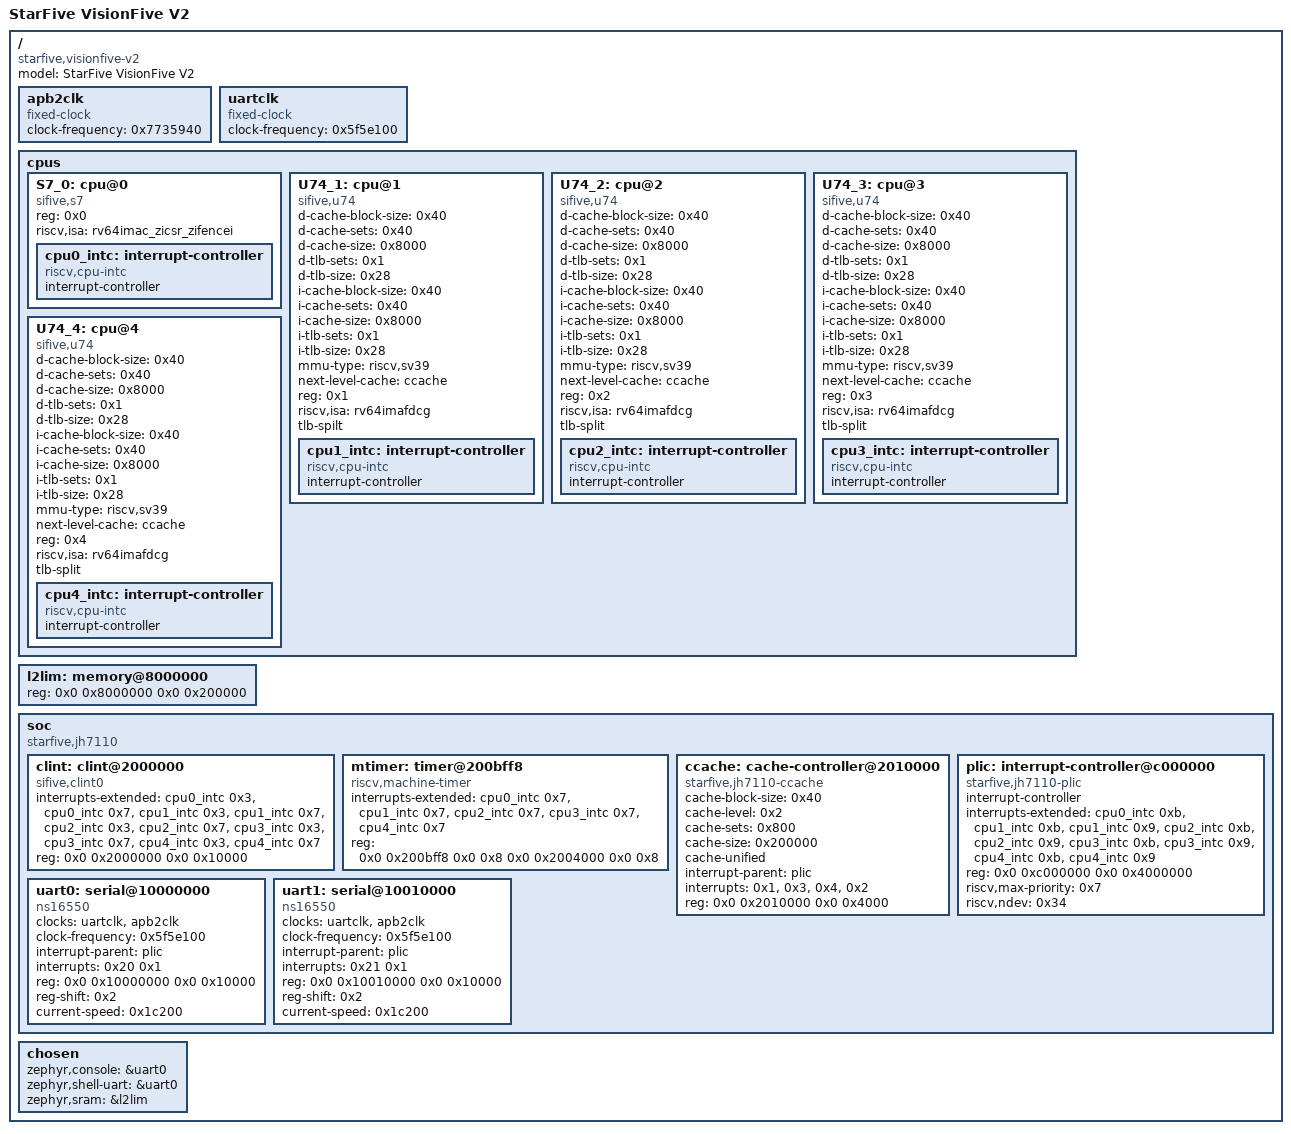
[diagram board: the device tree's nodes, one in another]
/dts-v1/;

/* node '/' defined in zephyr/dts/riscv/starfive/jh7110-clk.dtsi:8 */
/ {
	#address-cells = < 0x2 >;              /* in zephyr/dts/riscv/starfive/jh7110-visionfive-v2.dtsi:13 */
	#size-cells = < 0x2 >;                 /* in zephyr/dts/riscv/starfive/jh7110-visionfive-v2.dtsi:14 */
	model = "StarFive VisionFive V2";      /* in zephyr/boards/starfive/visionfive2/visionfive2.dts:12 */
	compatible = "starfive,visionfive-v2"; /* in zephyr/boards/starfive/visionfive2/visionfive2.dts:13 */

	/* node '/apb2clk' defined in zephyr/dts/riscv/starfive/jh7110-clk.dtsi:9 */
	apb2clk: apb2clk {
		#clock-cells = < 0x0 >;          /* in zephyr/dts/riscv/starfive/jh7110-clk.dtsi:10 */
		compatible = "fixed-clock";      /* in zephyr/dts/riscv/starfive/jh7110-clk.dtsi:11 */
		clock-frequency = < 0x7735940 >; /* in zephyr/dts/riscv/starfive/jh7110-clk.dtsi:12 */
		phandle = < 0x9 >;               /* in zephyr/dts/riscv/starfive/jh7110-visionfive-v2.dtsi:203 */
	};

	/* node '/uartclk' defined in zephyr/dts/riscv/starfive/jh7110-clk.dtsi:15 */
	uartclk: uartclk {
		#clock-cells = < 0x0 >;          /* in zephyr/dts/riscv/starfive/jh7110-clk.dtsi:16 */
		compatible = "fixed-clock";      /* in zephyr/dts/riscv/starfive/jh7110-clk.dtsi:17 */
		clock-frequency = < 0x5f5e100 >; /* in zephyr/dts/riscv/starfive/jh7110-clk.dtsi:18 */
		phandle = < 0x8 >;               /* in zephyr/dts/riscv/starfive/jh7110-visionfive-v2.dtsi:203 */
	};

	/* node '/cpus' defined in zephyr/dts/riscv/starfive/jh7110-visionfive-v2.dtsi:18 */
	cpus {
		#address-cells = < 0x1 >; /* in zephyr/dts/riscv/starfive/jh7110-visionfive-v2.dtsi:19 */
		#size-cells = < 0x0 >;    /* in zephyr/dts/riscv/starfive/jh7110-visionfive-v2.dtsi:20 */

		/* node '/cpus/cpu@0' defined in zephyr/dts/riscv/starfive/jh7110-visionfive-v2.dtsi:22 */
		S7_0: cpu@0 {
			compatible = "sifive,s7",
			             "riscv";                  /* in zephyr/dts/riscv/starfive/jh7110-visionfive-v2.dtsi:23 */
			device_type = "cpu";                   /* in zephyr/dts/riscv/starfive/jh7110-visionfive-v2.dtsi:24 */
			reg = < 0x0 >;                         /* in zephyr/dts/riscv/starfive/jh7110-visionfive-v2.dtsi:25 */
			riscv,isa = "rv64imac_zicsr_zifencei"; /* in zephyr/dts/riscv/starfive/jh7110-visionfive-v2.dtsi:26 */
			status = "okay";                       /* in zephyr/dts/riscv/starfive/jh7110-visionfive-v2.dtsi:27 */

			/* node '/cpus/cpu@0/interrupt-controller' defined in zephyr/dts/riscv/starfive/jh7110-visionfive-v2.dtsi:29 */
			cpu0_intc: interrupt-controller {
				compatible = "riscv,cpu-intc"; /* in zephyr/dts/riscv/starfive/jh7110-visionfive-v2.dtsi:30 */
				interrupt-controller;          /* in zephyr/dts/riscv/starfive/jh7110-visionfive-v2.dtsi:31 */
				#interrupt-cells = < 0x1 >;    /* in zephyr/dts/riscv/starfive/jh7110-visionfive-v2.dtsi:32 */
				phandle = < 0x2 >;             /* in zephyr/dts/riscv/starfive/jh7110-visionfive-v2.dtsi:155 */
			};
		};

		/* node '/cpus/cpu@1' defined in zephyr/dts/riscv/starfive/jh7110-visionfive-v2.dtsi:36 */
		U74_1: cpu@1 {
			compatible = "sifive,u74",
			             "riscv";           /* in zephyr/dts/riscv/starfive/jh7110-visionfive-v2.dtsi:37 */
			device_type = "cpu";            /* in zephyr/dts/riscv/starfive/jh7110-visionfive-v2.dtsi:38 */
			d-cache-block-size = < 0x40 >;  /* in zephyr/dts/riscv/starfive/jh7110-visionfive-v2.dtsi:39 */
			d-cache-sets = < 0x40 >;        /* in zephyr/dts/riscv/starfive/jh7110-visionfive-v2.dtsi:40 */
			d-cache-size = < 0x8000 >;      /* in zephyr/dts/riscv/starfive/jh7110-visionfive-v2.dtsi:41 */
			d-tlb-sets = < 0x1 >;           /* in zephyr/dts/riscv/starfive/jh7110-visionfive-v2.dtsi:42 */
			d-tlb-size = < 0x28 >;          /* in zephyr/dts/riscv/starfive/jh7110-visionfive-v2.dtsi:43 */
			i-cache-block-size = < 0x40 >;  /* in zephyr/dts/riscv/starfive/jh7110-visionfive-v2.dtsi:44 */
			i-cache-sets = < 0x40 >;        /* in zephyr/dts/riscv/starfive/jh7110-visionfive-v2.dtsi:45 */
			i-cache-size = < 0x8000 >;      /* in zephyr/dts/riscv/starfive/jh7110-visionfive-v2.dtsi:46 */
			i-tlb-sets = < 0x1 >;           /* in zephyr/dts/riscv/starfive/jh7110-visionfive-v2.dtsi:47 */
			i-tlb-size = < 0x28 >;          /* in zephyr/dts/riscv/starfive/jh7110-visionfive-v2.dtsi:48 */
			mmu-type = "riscv,sv39";        /* in zephyr/dts/riscv/starfive/jh7110-visionfive-v2.dtsi:49 */
			next-level-cache = < &ccache >; /* in zephyr/dts/riscv/starfive/jh7110-visionfive-v2.dtsi:50 */
			reg = < 0x1 >;                  /* in zephyr/dts/riscv/starfive/jh7110-visionfive-v2.dtsi:51 */
			riscv,isa = "rv64imafdcg";      /* in zephyr/dts/riscv/starfive/jh7110-visionfive-v2.dtsi:52 */
			tlb-spilt;                      /* in zephyr/dts/riscv/starfive/jh7110-visionfive-v2.dtsi:53 */

			/* node '/cpus/cpu@1/interrupt-controller' defined in zephyr/dts/riscv/starfive/jh7110-visionfive-v2.dtsi:55 */
			cpu1_intc: interrupt-controller {
				compatible = "riscv,cpu-intc"; /* in zephyr/dts/riscv/starfive/jh7110-visionfive-v2.dtsi:56 */
				#interrupt-cells = < 0x1 >;    /* in zephyr/dts/riscv/starfive/jh7110-visionfive-v2.dtsi:57 */
				interrupt-controller;          /* in zephyr/dts/riscv/starfive/jh7110-visionfive-v2.dtsi:58 */
				phandle = < 0x3 >;             /* in zephyr/dts/riscv/starfive/jh7110-visionfive-v2.dtsi:155 */
			};
		};

		/* node '/cpus/cpu@2' defined in zephyr/dts/riscv/starfive/jh7110-visionfive-v2.dtsi:62 */
		U74_2: cpu@2 {
			compatible = "sifive,u74",
			             "riscv";           /* in zephyr/dts/riscv/starfive/jh7110-visionfive-v2.dtsi:63 */
			device_type = "cpu";            /* in zephyr/dts/riscv/starfive/jh7110-visionfive-v2.dtsi:64 */
			d-cache-block-size = < 0x40 >;  /* in zephyr/dts/riscv/starfive/jh7110-visionfive-v2.dtsi:65 */
			d-cache-sets = < 0x40 >;        /* in zephyr/dts/riscv/starfive/jh7110-visionfive-v2.dtsi:66 */
			d-cache-size = < 0x8000 >;      /* in zephyr/dts/riscv/starfive/jh7110-visionfive-v2.dtsi:67 */
			d-tlb-sets = < 0x1 >;           /* in zephyr/dts/riscv/starfive/jh7110-visionfive-v2.dtsi:68 */
			d-tlb-size = < 0x28 >;          /* in zephyr/dts/riscv/starfive/jh7110-visionfive-v2.dtsi:69 */
			i-cache-block-size = < 0x40 >;  /* in zephyr/dts/riscv/starfive/jh7110-visionfive-v2.dtsi:70 */
			i-cache-sets = < 0x40 >;        /* in zephyr/dts/riscv/starfive/jh7110-visionfive-v2.dtsi:71 */
			i-cache-size = < 0x8000 >;      /* in zephyr/dts/riscv/starfive/jh7110-visionfive-v2.dtsi:72 */
			i-tlb-sets = < 0x1 >;           /* in zephyr/dts/riscv/starfive/jh7110-visionfive-v2.dtsi:73 */
			i-tlb-size = < 0x28 >;          /* in zephyr/dts/riscv/starfive/jh7110-visionfive-v2.dtsi:74 */
			mmu-type = "riscv,sv39";        /* in zephyr/dts/riscv/starfive/jh7110-visionfive-v2.dtsi:75 */
			next-level-cache = < &ccache >; /* in zephyr/dts/riscv/starfive/jh7110-visionfive-v2.dtsi:76 */
			reg = < 0x2 >;                  /* in zephyr/dts/riscv/starfive/jh7110-visionfive-v2.dtsi:77 */
			riscv,isa = "rv64imafdcg";      /* in zephyr/dts/riscv/starfive/jh7110-visionfive-v2.dtsi:78 */
			tlb-split;                      /* in zephyr/dts/riscv/starfive/jh7110-visionfive-v2.dtsi:79 */

			/* node '/cpus/cpu@2/interrupt-controller' defined in zephyr/dts/riscv/starfive/jh7110-visionfive-v2.dtsi:81 */
			cpu2_intc: interrupt-controller {
				compatible = "riscv,cpu-intc"; /* in zephyr/dts/riscv/starfive/jh7110-visionfive-v2.dtsi:82 */
				#interrupt-cells = < 0x1 >;    /* in zephyr/dts/riscv/starfive/jh7110-visionfive-v2.dtsi:83 */
				interrupt-controller;          /* in zephyr/dts/riscv/starfive/jh7110-visionfive-v2.dtsi:84 */
				phandle = < 0x4 >;             /* in zephyr/dts/riscv/starfive/jh7110-visionfive-v2.dtsi:155 */
			};
		};

		/* node '/cpus/cpu@3' defined in zephyr/dts/riscv/starfive/jh7110-visionfive-v2.dtsi:88 */
		U74_3: cpu@3 {
			compatible = "sifive,u74",
			             "riscv";           /* in zephyr/dts/riscv/starfive/jh7110-visionfive-v2.dtsi:89 */
			device_type = "cpu";            /* in zephyr/dts/riscv/starfive/jh7110-visionfive-v2.dtsi:90 */
			d-cache-block-size = < 0x40 >;  /* in zephyr/dts/riscv/starfive/jh7110-visionfive-v2.dtsi:91 */
			d-cache-sets = < 0x40 >;        /* in zephyr/dts/riscv/starfive/jh7110-visionfive-v2.dtsi:92 */
			d-cache-size = < 0x8000 >;      /* in zephyr/dts/riscv/starfive/jh7110-visionfive-v2.dtsi:93 */
			d-tlb-sets = < 0x1 >;           /* in zephyr/dts/riscv/starfive/jh7110-visionfive-v2.dtsi:94 */
			d-tlb-size = < 0x28 >;          /* in zephyr/dts/riscv/starfive/jh7110-visionfive-v2.dtsi:95 */
			i-cache-block-size = < 0x40 >;  /* in zephyr/dts/riscv/starfive/jh7110-visionfive-v2.dtsi:96 */
			i-cache-sets = < 0x40 >;        /* in zephyr/dts/riscv/starfive/jh7110-visionfive-v2.dtsi:97 */
			i-cache-size = < 0x8000 >;      /* in zephyr/dts/riscv/starfive/jh7110-visionfive-v2.dtsi:98 */
			i-tlb-sets = < 0x1 >;           /* in zephyr/dts/riscv/starfive/jh7110-visionfive-v2.dtsi:99 */
			i-tlb-size = < 0x28 >;          /* in zephyr/dts/riscv/starfive/jh7110-visionfive-v2.dtsi:100 */
			mmu-type = "riscv,sv39";        /* in zephyr/dts/riscv/starfive/jh7110-visionfive-v2.dtsi:101 */
			next-level-cache = < &ccache >; /* in zephyr/dts/riscv/starfive/jh7110-visionfive-v2.dtsi:102 */
			reg = < 0x3 >;                  /* in zephyr/dts/riscv/starfive/jh7110-visionfive-v2.dtsi:103 */
			riscv,isa = "rv64imafdcg";      /* in zephyr/dts/riscv/starfive/jh7110-visionfive-v2.dtsi:104 */
			tlb-split;                      /* in zephyr/dts/riscv/starfive/jh7110-visionfive-v2.dtsi:105 */

			/* node '/cpus/cpu@3/interrupt-controller' defined in zephyr/dts/riscv/starfive/jh7110-visionfive-v2.dtsi:107 */
			cpu3_intc: interrupt-controller {
				compatible = "riscv,cpu-intc"; /* in zephyr/dts/riscv/starfive/jh7110-visionfive-v2.dtsi:108 */
				#interrupt-cells = < 0x1 >;    /* in zephyr/dts/riscv/starfive/jh7110-visionfive-v2.dtsi:109 */
				interrupt-controller;          /* in zephyr/dts/riscv/starfive/jh7110-visionfive-v2.dtsi:110 */
				phandle = < 0x5 >;             /* in zephyr/dts/riscv/starfive/jh7110-visionfive-v2.dtsi:155 */
			};
		};

		/* node '/cpus/cpu@4' defined in zephyr/dts/riscv/starfive/jh7110-visionfive-v2.dtsi:114 */
		U74_4: cpu@4 {
			compatible = "sifive,u74",
			             "riscv";           /* in zephyr/dts/riscv/starfive/jh7110-visionfive-v2.dtsi:115 */
			device_type = "cpu";            /* in zephyr/dts/riscv/starfive/jh7110-visionfive-v2.dtsi:116 */
			d-cache-block-size = < 0x40 >;  /* in zephyr/dts/riscv/starfive/jh7110-visionfive-v2.dtsi:117 */
			d-cache-sets = < 0x40 >;        /* in zephyr/dts/riscv/starfive/jh7110-visionfive-v2.dtsi:118 */
			d-cache-size = < 0x8000 >;      /* in zephyr/dts/riscv/starfive/jh7110-visionfive-v2.dtsi:119 */
			d-tlb-sets = < 0x1 >;           /* in zephyr/dts/riscv/starfive/jh7110-visionfive-v2.dtsi:120 */
			d-tlb-size = < 0x28 >;          /* in zephyr/dts/riscv/starfive/jh7110-visionfive-v2.dtsi:121 */
			i-cache-block-size = < 0x40 >;  /* in zephyr/dts/riscv/starfive/jh7110-visionfive-v2.dtsi:122 */
			i-cache-sets = < 0x40 >;        /* in zephyr/dts/riscv/starfive/jh7110-visionfive-v2.dtsi:123 */
			i-cache-size = < 0x8000 >;      /* in zephyr/dts/riscv/starfive/jh7110-visionfive-v2.dtsi:124 */
			i-tlb-sets = < 0x1 >;           /* in zephyr/dts/riscv/starfive/jh7110-visionfive-v2.dtsi:125 */
			i-tlb-size = < 0x28 >;          /* in zephyr/dts/riscv/starfive/jh7110-visionfive-v2.dtsi:126 */
			mmu-type = "riscv,sv39";        /* in zephyr/dts/riscv/starfive/jh7110-visionfive-v2.dtsi:127 */
			next-level-cache = < &ccache >; /* in zephyr/dts/riscv/starfive/jh7110-visionfive-v2.dtsi:128 */
			reg = < 0x4 >;                  /* in zephyr/dts/riscv/starfive/jh7110-visionfive-v2.dtsi:129 */
			riscv,isa = "rv64imafdcg";      /* in zephyr/dts/riscv/starfive/jh7110-visionfive-v2.dtsi:130 */
			tlb-split;                      /* in zephyr/dts/riscv/starfive/jh7110-visionfive-v2.dtsi:131 */

			/* node '/cpus/cpu@4/interrupt-controller' defined in zephyr/dts/riscv/starfive/jh7110-visionfive-v2.dtsi:133 */
			cpu4_intc: interrupt-controller {
				compatible = "riscv,cpu-intc"; /* in zephyr/dts/riscv/starfive/jh7110-visionfive-v2.dtsi:134 */
				#interrupt-cells = < 0x1 >;    /* in zephyr/dts/riscv/starfive/jh7110-visionfive-v2.dtsi:135 */
				interrupt-controller;          /* in zephyr/dts/riscv/starfive/jh7110-visionfive-v2.dtsi:136 */
				phandle = < 0x6 >;             /* in zephyr/dts/riscv/starfive/jh7110-visionfive-v2.dtsi:155 */
			};
		};
	};

	/* node '/memory@8000000' defined in zephyr/dts/riscv/starfive/jh7110-visionfive-v2.dtsi:141 */
	l2lim: memory@8000000 {
		device_type = "memory";               /* in zephyr/dts/riscv/starfive/jh7110-visionfive-v2.dtsi:142 */
		reg = < 0x0 0x8000000 0x0 0x200000 >; /* in zephyr/dts/riscv/starfive/jh7110-visionfive-v2.dtsi:143 */
	};

	/* node '/soc' defined in zephyr/dts/riscv/starfive/jh7110-visionfive-v2.dtsi:146 */
	soc {
		#address-cells = < 0x2 >;       /* in zephyr/dts/riscv/starfive/jh7110-visionfive-v2.dtsi:147 */
		#size-cells = < 0x2 >;          /* in zephyr/dts/riscv/starfive/jh7110-visionfive-v2.dtsi:148 */
		#clock-cells = < 0x1 >;         /* in zephyr/dts/riscv/starfive/jh7110-visionfive-v2.dtsi:149 */
		compatible = "starfive,jh7110",
		             "simple-bus";      /* in zephyr/dts/riscv/starfive/jh7110-visionfive-v2.dtsi:150 */
		ranges;                         /* in zephyr/dts/riscv/starfive/jh7110-visionfive-v2.dtsi:151 */

		/* node '/soc/clint@2000000' defined in zephyr/dts/riscv/starfive/jh7110-visionfive-v2.dtsi:153 */
		clint: clint@2000000 {
			compatible = "sifive,clint0";                                                                                 /* in zephyr/dts/riscv/starfive/jh7110-visionfive-v2.dtsi:154 */
			interrupts-extended = < &cpu0_intc 0x3 &cpu0_intc 0x7 &cpu1_intc 0x3 &cpu1_intc 0x7 &cpu2_intc 0x3 &cpu2_intc
			                        0x7 &cpu3_intc 0x3 &cpu3_intc 0x7 &cpu4_intc 0x3 &cpu4_intc 0x7 >;                    /* in zephyr/dts/riscv/starfive/jh7110-visionfive-v2.dtsi:155 */
			reg = < 0x0 0x2000000 0x0 0x10000 >;                                                                          /* in zephyr/dts/riscv/starfive/jh7110-visionfive-v2.dtsi:160 */
		};

		/* node '/soc/timer@200bff8' defined in zephyr/dts/riscv/starfive/jh7110-visionfive-v2.dtsi:163 */
		mtimer: timer@200bff8 {
			compatible = "riscv,machine-timer";                                                                   /* in zephyr/dts/riscv/starfive/jh7110-visionfive-v2.dtsi:164 */
			interrupts-extended = < &cpu0_intc 0x7 &cpu1_intc 0x7 &cpu2_intc 0x7 &cpu3_intc 0x7 &cpu4_intc 0x7 >; /* in zephyr/dts/riscv/starfive/jh7110-visionfive-v2.dtsi:165 */
			reg = < 0x0 0x200bff8 0x0 0x8 0x0 0x2004000 0x0 0x8 >;                                                /* in zephyr/dts/riscv/starfive/jh7110-visionfive-v2.dtsi:170 */
			reg-names = "mtime",
			            "mtimecmp";                                                                               /* in zephyr/dts/riscv/starfive/jh7110-visionfive-v2.dtsi:171 */
		};

		/* node '/soc/cache-controller@2010000' defined in zephyr/dts/riscv/starfive/jh7110-visionfive-v2.dtsi:174 */
		ccache: cache-controller@2010000 {
			cache-block-size = < 0x40 >;           /* in zephyr/dts/riscv/starfive/jh7110-visionfive-v2.dtsi:175 */
			cache-level = < 0x2 >;                 /* in zephyr/dts/riscv/starfive/jh7110-visionfive-v2.dtsi:176 */
			cache-sets = < 0x800 >;                /* in zephyr/dts/riscv/starfive/jh7110-visionfive-v2.dtsi:177 */
			cache-size = < 0x200000 >;             /* in zephyr/dts/riscv/starfive/jh7110-visionfive-v2.dtsi:178 */
			cache-unified;                         /* in zephyr/dts/riscv/starfive/jh7110-visionfive-v2.dtsi:179 */
			compatible = "starfive,jh7110-ccache",
			             "sifive,ccache0",
			             "cache";                  /* in zephyr/dts/riscv/starfive/jh7110-visionfive-v2.dtsi:180 */
			interrupt-parent = < &plic >;          /* in zephyr/dts/riscv/starfive/jh7110-visionfive-v2.dtsi:181 */
			interrupts = < 0x1 >,
			             < 0x3 >,
			             < 0x4 >,
			             < 0x2 >;                  /* in zephyr/dts/riscv/starfive/jh7110-visionfive-v2.dtsi:182 */
			reg = < 0x0 0x2010000 0x0 0x4000 >;    /* in zephyr/dts/riscv/starfive/jh7110-visionfive-v2.dtsi:183 */
			phandle = < 0x1 >;                     /* in zephyr/dts/riscv/starfive/jh7110-visionfive-v2.dtsi:50 */
		};

		/* node '/soc/interrupt-controller@c000000' defined in zephyr/dts/riscv/starfive/jh7110-visionfive-v2.dtsi:186 */
		plic: interrupt-controller@c000000 {
			compatible = "starfive,jh7110-plic",
			             "sifive,plic-1.0.0";         /* in zephyr/dts/riscv/starfive/jh7110-visionfive-v2.dtsi:187 */
			#address-cells = < 0x0 >;                 /* in zephyr/dts/riscv/starfive/jh7110-visionfive-v2.dtsi:188 */
			#interrupt-cells = < 0x2 >;               /* in zephyr/dts/riscv/starfive/jh7110-visionfive-v2.dtsi:189 */
			interrupt-controller;                     /* in zephyr/dts/riscv/starfive/jh7110-visionfive-v2.dtsi:190 */
			interrupts-extended = < &cpu0_intc 0xb >,
			                      < &cpu1_intc 0xb >,
			                      < &cpu1_intc 0x9 >,
			                      < &cpu2_intc 0xb >,
			                      < &cpu2_intc 0x9 >,
			                      < &cpu3_intc 0xb >,
			                      < &cpu3_intc 0x9 >,
			                      < &cpu4_intc 0xb >,
			                      < &cpu4_intc 0x9 >; /* in zephyr/dts/riscv/starfive/jh7110-visionfive-v2.dtsi:191 */
			reg = < 0x0 0xc000000 0x0 0x4000000 >;    /* in zephyr/dts/riscv/starfive/jh7110-visionfive-v2.dtsi:196 */
			riscv,max-priority = < 0x7 >;             /* in zephyr/dts/riscv/starfive/jh7110-visionfive-v2.dtsi:197 */
			riscv,ndev = < 0x34 >;                    /* in zephyr/dts/riscv/starfive/jh7110-visionfive-v2.dtsi:198 */
			phandle = < 0x7 >;                        /* in zephyr/dts/riscv/starfive/jh7110-visionfive-v2.dtsi:181 */
		};

		/* node '/soc/serial@10000000' defined in zephyr/dts/riscv/starfive/jh7110-visionfive-v2.dtsi:201 */
		uart0: serial@10000000 {
			compatible = "ns16550",
			             "snps,dw-apb-uart";      /* in zephyr/dts/riscv/starfive/jh7110-visionfive-v2.dtsi:202 */
			clocks = < &uartclk >,
			         < &apb2clk >;                /* in zephyr/dts/riscv/starfive/jh7110-visionfive-v2.dtsi:203 */
			clock-names = "baudclk",
			              "apb_pclk";             /* in zephyr/dts/riscv/starfive/jh7110-visionfive-v2.dtsi:204 */
			clock-frequency = < 0x5f5e100 >;      /* in zephyr/dts/riscv/starfive/jh7110-visionfive-v2.dtsi:205 */
			interrupt-parent = < &plic >;         /* in zephyr/dts/riscv/starfive/jh7110-visionfive-v2.dtsi:207 */
			interrupts = < 0x20 0x1 >;            /* in zephyr/dts/riscv/starfive/jh7110-visionfive-v2.dtsi:208 */
			reg = < 0x0 0x10000000 0x0 0x10000 >; /* in zephyr/dts/riscv/starfive/jh7110-visionfive-v2.dtsi:209 */
			reg-shift = < 0x2 >;                  /* in zephyr/dts/riscv/starfive/jh7110-visionfive-v2.dtsi:210 */
			status = "okay";                      /* in zephyr/boards/starfive/visionfive2/visionfive2.dts:23 */
			current-speed = < 0x1c200 >;          /* in zephyr/boards/starfive/visionfive2/visionfive2.dts:24 */
		};

		/* node '/soc/serial@10010000' defined in zephyr/dts/riscv/starfive/jh7110-visionfive-v2.dtsi:214 */
		uart1: serial@10010000 {
			compatible = "ns16550",
			             "snps,dw-apb-uart";      /* in zephyr/dts/riscv/starfive/jh7110-visionfive-v2.dtsi:215 */
			clocks = < &uartclk >,
			         < &apb2clk >;                /* in zephyr/dts/riscv/starfive/jh7110-visionfive-v2.dtsi:216 */
			clock-names = "baudclk",
			              "apb_pclk";             /* in zephyr/dts/riscv/starfive/jh7110-visionfive-v2.dtsi:217 */
			clock-frequency = < 0x5f5e100 >;      /* in zephyr/dts/riscv/starfive/jh7110-visionfive-v2.dtsi:218 */
			interrupt-parent = < &plic >;         /* in zephyr/dts/riscv/starfive/jh7110-visionfive-v2.dtsi:220 */
			interrupts = < 0x21 0x1 >;            /* in zephyr/dts/riscv/starfive/jh7110-visionfive-v2.dtsi:221 */
			reg = < 0x0 0x10010000 0x0 0x10000 >; /* in zephyr/dts/riscv/starfive/jh7110-visionfive-v2.dtsi:222 */
			reg-shift = < 0x2 >;                  /* in zephyr/dts/riscv/starfive/jh7110-visionfive-v2.dtsi:223 */
			status = "okay";                      /* in zephyr/boards/starfive/visionfive2/visionfive2.dts:28 */
			current-speed = < 0x1c200 >;          /* in zephyr/boards/starfive/visionfive2/visionfive2.dts:29 */
		};
	};

	/* node '/chosen' defined in zephyr/boards/starfive/visionfive2/visionfive2.dts:15 */
	chosen {
		zephyr,console = &uart0;    /* in zephyr/boards/starfive/visionfive2/visionfive2.dts:16 */
		zephyr,shell-uart = &uart0; /* in zephyr/boards/starfive/visionfive2/visionfive2.dts:17 */
		zephyr,sram = &l2lim;       /* in zephyr/boards/starfive/visionfive2/visionfive2.dts:18 */
	};
};
